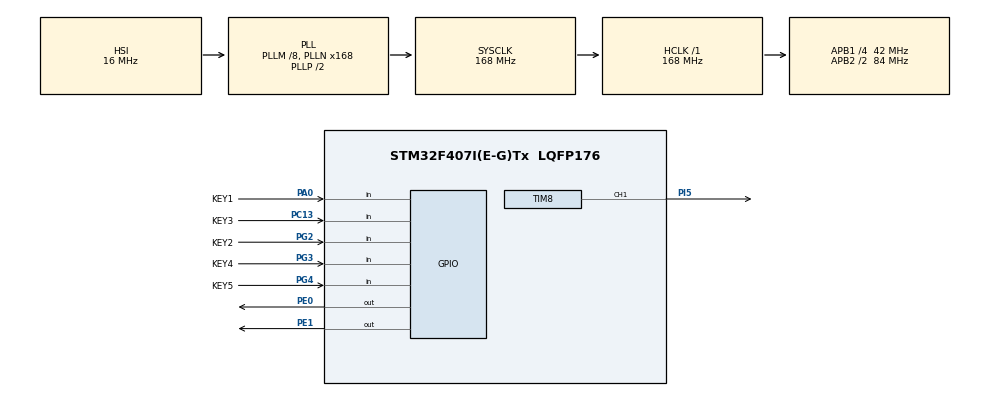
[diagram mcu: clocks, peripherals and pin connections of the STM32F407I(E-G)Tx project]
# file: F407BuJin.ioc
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Mcu.Family=STM32F4
Mcu.Name=STM32F407I(E-G)Tx
Mcu.Package=LQFP176
NVIC.PriorityGroup=NVIC_PRIORITYGROUP_4
NVIC.TIM8_CC_IRQn=true\:0\:0\:false\:false\:true\:true\:true\:true
PA0-WKUP.GPIO_Label=KEY1
PA0-WKUP.Signal=GPIO_Input
PA13.Mode=Serial_Wire
PA13.Signal=SYS_JTMS-SWDIO
PA14.Mode=Serial_Wire
PA14.Signal=SYS_JTCK-SWCLK
PC13-ANTI_TAMP.GPIO_Label=KEY3
PC13-ANTI_TAMP.Signal=GPIO_Input
PE0.Signal=GPIO_Output
PE1.Signal=GPIO_Output
PG2.GPIO_Label=KEY2
PG2.Signal=GPIO_Input
PG3.GPIO_Label=KEY4
PG3.Signal=GPIO_Input
PG4.GPIO_Label=KEY5
PG4.Signal=GPIO_Input
PH0-OSC_IN.Mode=HSE-External-Oscillator
PH0-OSC_IN.Signal=RCC_OSC_IN
PH1-OSC_OUT.Mode=HSE-External-Oscillator
PH1-OSC_OUT.Signal=RCC_OSC_OUT
PI5.Signal=S_TIM8_CH1
ProjectManager.HeapSize=0x200
ProjectManager.StackSize=0x400
ProjectManager.TargetToolchain=MDK-ARM V5.32
RCC.48MHZClocksFreq_Value=84000000
RCC.AHBFreq_Value=168000000
RCC.APB1CLKDivider=RCC_HCLK_DIV4
RCC.APB1Freq_Value=42000000
RCC.APB1TimFreq_Value=84000000
RCC.APB2CLKDivider=RCC_HCLK_DIV2
RCC.APB2Freq_Value=84000000
RCC.APB2TimFreq_Value=168000000
RCC.CortexFreq_Value=168000000
RCC.HCLKFreq_Value=168000000
RCC.HSE_VALUE=25000000
RCC.HSI_VALUE=16000000
RCC.LSE_VALUE=32768
RCC.PLLM=8
RCC.PLLN=168
RCC.SYSCLKFreq_VALUE=168000000
RCC.SYSCLKSource=RCC_SYSCLKSOURCE_PLLCLK
RCC.VCOOutputFreq_Value=336000000
SH.S_TIM8_CH1.0=TIM8_CH1,Output Compare1 CH1
TIM8.Channel-Output\ Compare1\ CH1=TIM_CHANNEL_1
TIM8.Prescaler=5
TIM8.Pulse-Output\ Compare1\ CH1=3000
VP_TIM8_VS_ClockSourceINT.Mode=Internal
board=custom

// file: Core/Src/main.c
/* USER CODE BEGIN Header */
/**
  ******************************************************************************
  * @file           : main.c
  * @brief          : Main program body
  ******************************************************************************
  * @attention
  *
  * Copyright (c) 2023 STMicroelectronics.
  * All rights reserved.
  *
  * This software is licensed under terms that can be found in the LICENSE file
  * in the root directory of this software component.
  * If no LICENSE file comes with this software, it is provided AS-IS.
  *
  ******************************************************************************
  */
/* USER CODE END Header */
#include "main.h"
#include "tim.h"
#include "gpio.h"

/* USER CODE BEGIN Includes */
#include "T_Speed.h"
// 速度最大值由驱动器和电机决定，有些最大是1800，有些可以达到4000
__IO uint32_t set_speed  = 3000;         // 速度 单位为0.05rad/sec
// 加速度和减速度选取一般根据实际需要，值越大速度变化越快，加减速阶段比较抖动
// 所以加速度和减速度值一般是在实际应用中多尝试出来的结果
__IO uint32_t step_accel = 10;         // 加速度 单位为0.025rad/sec^2
__IO uint32_t step_decel = 10;         // 减速度 单位为0.025rad/sec^2

/* USER CODE END Includes */

void SystemClock_Config(void);

int main(void)
{
  /* USER CODE BEGIN 1 */
int i=0,dir_val=0;
  /* USER CODE END 1 */

  /* MCU Configuration--------------------------------------------------------*/

  /* Reset of all peripherals, Initializes the Flash interface and the Systick. */
  HAL_Init();

  /* Configure the system clock */
  SystemClock_Config();

  /* Initialize all configured peripherals */
  MX_GPIO_Init();
  MX_TIM8_Init();
  /* USER CODE BEGIN 2 */
 /* 确定定时器 */
  HAL_TIM_Base_Start(&htim8);
  /* 使能中断 关闭比较输出*/
  HAL_TIM_OC_Start_IT(&htim8,TIM_CHANNEL_1);
  TIM_CCxChannelCmd(TIM8,TIM_CHANNEL_1,TIM_CCx_DISABLE);
  /* USER CODE END 2 */

  /* Infinite loop */
  while (1)
  {

    /* USER CODE BEGIN 3 */

	dir_val=(i++ % 2) ? CW : CCW;

		if(dir_val)
		{
			STEPMOTOR_AxisMoveRel(6400*80, step_accel, step_decel, set_speed);
		}
		else
		{
			STEPMOTOR_AxisMoveRel(-6400*80, step_accel, step_decel, set_speed);
		}

		HAL_Delay(5000);//要等旋转再反向旋转

	}

  /* USER CODE END 3 */
}

void SystemClock_Config(void)
{
  RCC_OscInitTypeDef RCC_OscInitStruct = {0};
  RCC_ClkInitTypeDef RCC_ClkInitStruct = {0};

  /** Configure the main internal regulator output voltage
  */
  __HAL_RCC_PWR_CLK_ENABLE();
  __HAL_PWR_VOLTAGESCALING_CONFIG(PWR_REGULATOR_VOLTAGE_SCALE1);

  /** Initializes the RCC Oscillators according to the specified parameters
  * in the RCC_OscInitTypeDef structure.
  */
  RCC_OscInitStruct.OscillatorType = RCC_OSCILLATORTYPE_HSI;
  RCC_OscInitStruct.HSIState = RCC_HSI_ON;
  RCC_OscInitStruct.HSICalibrationValue = RCC_HSICALIBRATION_DEFAULT;
  RCC_OscInitStruct.PLL.PLLState = RCC_PLL_ON;
  RCC_OscInitStruct.PLL.PLLSource = RCC_PLLSOURCE_HSI;
  RCC_OscInitStruct.PLL.PLLM = 8;
  RCC_OscInitStruct.PLL.PLLN = 168;
  RCC_OscInitStruct.PLL.PLLP = RCC_PLLP_DIV2;
  RCC_OscInitStruct.PLL.PLLQ = 4;
  if (HAL_RCC_OscConfig(&RCC_OscInitStruct) != HAL_OK)
  {
    Error_Handler();
  }

  /** Initializes the CPU, AHB and APB buses clocks
  */
  RCC_ClkInitStruct.ClockType = RCC_CLOCKTYPE_HCLK|RCC_CLOCKTYPE_SYSCLK
                              |RCC_CLOCKTYPE_PCLK1|RCC_CLOCKTYPE_PCLK2;
  RCC_ClkInitStruct.SYSCLKSource = RCC_SYSCLKSOURCE_PLLCLK;
  RCC_ClkInitStruct.AHBCLKDivider = RCC_SYSCLK_DIV1;
  RCC_ClkInitStruct.APB1CLKDivider = RCC_HCLK_DIV4;
  RCC_ClkInitStruct.APB2CLKDivider = RCC_HCLK_DIV2;

  if (HAL_RCC_ClockConfig(&RCC_ClkInitStruct, FLASH_LATENCY_5) != HAL_OK)
  {
    Error_Handler();
  }

  HAL_RCC_EnableCSS();                                            // 使能CSS功能，优先使用外部晶振，内部时钟源为备用

 	// HAL_RCC_GetHCLKFreq()/1000    1ms中断一次
	// HAL_RCC_GetHCLKFreq()/100000	 10us中断一次
	// HAL_RCC_GetHCLKFreq()/1000000 1us中断一次
  HAL_SYSTICK_Config(HAL_RCC_GetHCLKFreq()/1000);                 // 配置并启动系统滴答定时器
  /* 系统滴答定时器时钟源 */
  HAL_SYSTICK_CLKSourceConfig(SYSTICK_CLKSOURCE_HCLK);

  /* 系统滴答定时器中断优先级配置 */
  HAL_NVIC_SetPriority(SysTick_IRQn, 0, 0);
}

void Error_Handler(void)
{
  __disable_irq();
  while (1)
  {
  }
}
